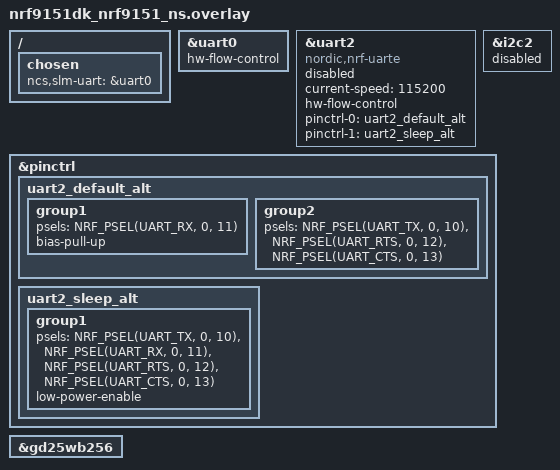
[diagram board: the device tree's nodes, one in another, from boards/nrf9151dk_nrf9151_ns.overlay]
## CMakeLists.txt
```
#
# Copyright (c) 2019 Nordic Semiconductor
#
# SPDX-License-Identifier: LicenseRef-Nordic-5-Clause
#

cmake_minimum_required(VERSION 3.20.0)

find_package(Zephyr REQUIRED HINTS $ENV{ZEPHYR_BASE})
project(serial_lte_modem)

# NORDIC SDK APP START
target_sources(app PRIVATE src/main.c)
target_sources(app PRIVATE src/slm_util.c)
target_sources(app PRIVATE src/slm_ctrl_pin.c)
target_sources(app PRIVATE src/slm_settings.c)
target_sources(app PRIVATE src/slm_at_host.c)
target_sources(app PRIVATE src/slm_at_commands.c)
target_sources(app PRIVATE src/slm_at_socket.c)
target_sources(app PRIVATE src/slm_at_tcp_proxy.c)
target_sources(app PRIVATE src/slm_at_udp_proxy.c)
target_sources(app PRIVATE src/slm_at_icmp.c)
target_sources(app PRIVATE src/slm_at_fota.c)
target_sources(app PRIVATE src/slm_uart_handler.c)
# NORDIC SDK APP END
target_sources_ifdef(CONFIG_SLM_SMS app PRIVATE src/slm_at_sms.c)
target_sources_ifdef(CONFIG_SLM_PPP app PRIVATE src/slm_ppp.c)
target_sources_ifdef(CONFIG_SLM_CMUX app PRIVATE src/slm_cmux.c)

add_subdirectory_ifdef(CONFIG_SLM_GNSS src/gnss)
add_subdirectory_ifdef(CONFIG_SLM_NRF_CLOUD src/nrfcloud)
add_subdirectory_ifdef(CONFIG_SLM_MQTTC src/mqtt_c)
add_subdirectory_ifdef(CONFIG_SLM_HTTPC src/http_c)
add_subdirectory_ifdef(CONFIG_SLM_TWI src/twi)
add_subdirectory_ifdef(CONFIG_SLM_GPIO src/gpio)
add_subdirectory_ifdef(CONFIG_SLM_CARRIER src/lwm2m_carrier)
add_subdirectory_ifdef(CONFIG_SLM_NATIVE_TLS src/nativetls)
if (CONFIG_SLM_FTPC OR CONFIG_SLM_TFTPC)
        add_subdirectory(src/ftp_c)
endif()

zephyr_include_directories(src)
```

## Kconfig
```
#
# Copyright (c) 2019 Nordic Semiconductor
#
# SPDX-License-Identifier: LicenseRef-Nordic-5-Clause
#

source "Kconfig.zephyr"

menu "Nordic Serial LTE Modem"

config SLM_CUSTOMER_VERSION
	string "Customer version string"
	help
	   This version is reported together with baseline versions by AT command "#XSLMVER".

config SLM_AT_MAX_PARAM
	int "Maximum number of parameters in AT command"
	default 42

#
# external XTAL for UART
#
config SLM_EXTERNAL_XTAL
	bool "Use external XTAL for UARTE"
	default y

#
# AT command terminator
#
choice
	prompt "Termination mode"
	default SLM_CR_LF_TERMINATION
	help
		Sets the command terminator used by the serial terminal.
		Available options are:
		-  CR termination
		-  LF termination
		-  CR+LF termination
	config SLM_CR_TERMINATION
		bool "CR termination"
	config SLM_LF_TERMINATION
		bool "LF termination"
	config SLM_CR_LF_TERMINATION
		bool "CR+LF termination"
endchoice

#
# UART buffers (when CMUX is not in use)
#
config SLM_UART_RX_BUF_COUNT
	int "Receive buffers for UART"
	range 2 4
	default 3
	help
	  Amount of buffers for receiving (RX) UART traffic.
	  If the buffers are full, UART RX will be disabled until the buffers are processed.
	  These buffers are not used when CMUX is in use.

config SLM_UART_RX_BUF_SIZE
	int "Receive buffer size for UART"
	range 128 4096
	default 256
	help
	  Amount of received (RX), unprocessed, UART traffic that can be held by single buffer.
	  These buffers are not used when CMUX is in use.

config SLM_UART_TX_BUF_SIZE
	int "Send buffer size for UART"
	range 128 4096
	default 256
	help
	  Amount of UART traffic waiting to be sent (TX), that can be held.
	  If the buffers are full, will send synchronously.
	  These buffers are not used when CMUX is in use.

#
# GPIO functionality
#
config SLM_START_SLEEP
	bool "Enter sleep on startup"
	help
	  If enabled, the SiP is put into deep sleep when powered on.
	  It can then be started using SLM_POWER_PIN.

config SLM_POWER_PIN
	int "Power pin"
	default -1
	help
	  Interface GPIO pin used to put the SiP into deep sleep and wake up from it or exit idle.
	  The pin is configured with a pull up and must be pulled down shortly to perform one power off or wake up operation.

config SLM_INDICATE_PIN
	int "Indicate pin"
	default -1
	help
	  Interface GPIO pin used to indicate that data is available when SLM is idle (after #XSLEEP=2 AT command).

config SLM_INDICATE_TIME
	int "Indication period"
	default 100
	help
	  GPIO active indication time in milliseconds. This setting specify the period length for the pin to be active

#
# LTE network automatic attach
#
config SLM_AUTO_CONNECT
	bool "Automatically connect to the LTE network on start-up or after a reset"
	help
	  Enables automatic connection to the LTE network using the PDN configuration defined in 'slm_auto_connect.h'.

#
# TCP/TLS proxy
#
config SLM_TCP_POLL_TIME
	int "Poll time-out in seconds for TCP connection"
	default 10

config SLM_UDP_POLL_TIME
	int "Poll time-out in seconds for UDP connection"
	default 10

#
# Data mode
#
config SLM_DATAMODE_TERMINATOR
	string "Pattern string to terminate data mode"
	default "+++"
	help
	  Use a pattern to terminate data mode

config SLM_DATAMODE_URC
	bool "Send URC in data mode"
	help
	  Report result of data mode sending

config SLM_DATAMODE_BUF_SIZE
	int "Buffer size for data mode"
	range 1024 8192
	default 4096
	help
	  Size of the buffer for data received in data mode.

#
# Configurable services
#
config SLM_SMS
	bool "SMS support in SLM"
	default y
	select SMS
	help
	  Support SMS send/receive in plain text

config SLM_GNSS
	bool "GNSS support in SLM"
	default y

config SLM_NRF_CLOUD
	bool "nRF Cloud support in SLM"
	default y

config SLM_FULL_FOTA
	bool "Full modem FOTA support in SLM"
	default n
	depends on !BOARD_THINGY91_NRF9160_NS

config SLM_PPP
	bool "PPP support in SLM"
	help
	  When enabled, SLM automatically brings up/down the PPP link
	  when the LTE link (default PDN) is connected/disconnected,
	  regardless of what is done with AT#XPPP.

if SLM_PPP

config SLM_PPP_FALLBACK_MTU
	int "Fallback MTU to be used by PPP"
	default 1280
	help
	  PPP tries to retrieve the cellular link MTU from the modem (using `AT+CGCONTRDP=0`).
	  If no MTU is returned by the modem, this value will be used as a fallback.
	  The MTU will be used for sending and receiving of data on both the PPP and cellular links.

endif

config SLM_CMUX
	bool "CMUX support in SLM"

config SLM_CMUX_UART_BUFFER_SIZE
	int "UART buffer size for CMUX"
	depends on SLM_CMUX
	default 6000
	help
	  Size of the buffer for data received in CMUX mode.
	  Same buffer size is used for both RX and TX.

config SLM_CMUX_NOTIFICATION_TX_BUFFER_SIZE
	int "TX buffer size for unsolicited notifications in CMUX"
	depends on SLM_CMUX
	default 4096
	help
	  Unsolicited notifications need to be buffered with CMUX.
	  Notifications longer than this size will get truncated.
	  This can be reduced if your use cases do not require lengthy notifications.
	  Note: %NCELLMEAS notifications can be nearly 4kB in size,
	  which explains the default value.

if SLM_CMUX && SLM_PPP

config SLM_MODEM_CELLULAR
	bool "Compatibility with cellular modem driver"
	help
	  Enables compatibility with a host that uses the cellular modem driver. Compared to clients,
	  such as pppd, the cellular modem driver retains more control on how the PPP link
	  is brought up and down.

config SLM_CMUX_AUTOMATIC_FALLBACK_ON_PPP_STOPPAGE
	bool "AT channel automatic fallback to DLCI 1 when PPP stops."
	default y if SLM_MODEM_CELLULAR
	help
	  This is mainly intended for compatibility with Zephyr's cellular modem driver.
	  If enabled, when PPP stops (which happens automatically when the LTE link goes down)
	  CMUX will make the AT channel be on DLCI 1. This only has an effect if it had been
	  configured to be elsewhere, e.g. with AT#XCMUX=2.

endif

if SLM_CMUX || SLM_PPP

config SLM_MODEM_PIPE_TIMEOUT
	int "Timeout for the CMUX and PPP modem pipe operations in seconds"
	default 10

endif

config SLM_SKIP_READY_MSG
	bool "Skip ready message"
	help
	  Skip sending the ready message when the application is powered on.


module = SLM
module-str = serial modem
source "${ZEPHYR_BASE}/subsys/logging/Kconfig.template.log_config"

rsource "src/ftp_c/Kconfig"
rsource "src/mqtt_c/Kconfig"
rsource "src/http_c/Kconfig"
rsource "src/twi/Kconfig"
rsource "src/gpio/Kconfig"
rsource "src/lwm2m_carrier/Kconfig"
rsource "src/gnss/Kconfig"
rsource "src/nativetls/Kconfig"

endmenu
```

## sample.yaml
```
sample:
  name: Serial LTE Modem
tests:
  applications.serial_lte_modem:
    sysbuild: true
    build_only: true
    platform_allow:
      - nrf9160dk/nrf9160/ns
      - nrf9161dk/nrf9161/ns
      - nrf9151dk/nrf9151/ns
      - nrf9131ek/nrf9131/ns
      - thingy91/nrf9160/ns
      - thingy91x/nrf9151/ns
    integration_platforms:
      - nrf9160dk/nrf9160/ns
      - nrf9161dk/nrf9161/ns
      - nrf9151dk/nrf9151/ns
      - nrf9131ek/nrf9131/ns
      - thingy91/nrf9160/ns
      - thingy91x/nrf9151/ns
    tags:
      - ci_build
      - sysbuild
      - ci_applications_serial_lte_modem
  applications.serial_lte_modem.extmcu:
    sysbuild: true
    build_only: true
    extra_args:
      - EXTRA_DTC_OVERLAY_FILE="overlay-external-mcu.overlay"
    extra_configs:
      - CONFIG_SLM_POWER_PIN=31
      - CONFIG_SLM_INDICATE_PIN=30
    platform_allow:
      - nrf9160dk/nrf9160/ns
      - nrf9161dk/nrf9161/ns
      - nrf9151dk/nrf9151/ns
    integration_platforms:
      - nrf9151dk/nrf9151/ns
    tags:
      - ci_build
      - sysbuild
      - ci_applications_serial_lte_modem
  applications.serial_lte_modem.ppp_without_cmux:
    sysbuild: true
    build_only: true
    extra_args:
      - EXTRA_CONF_FILE="overlay-ppp.conf"
      - EXTRA_DTC_OVERLAY_FILE="overlay-ppp-without-cmux.overlay"
    platform_allow:
      - nrf9160dk/nrf9160/ns
      - nrf9161dk/nrf9161/ns
      - nrf9151dk/nrf9151/ns
      - nrf9131ek/nrf9131/ns
      - thingy91/nrf9160/ns
      - thingy91x/nrf9151/ns
    integration_platforms:
      - nrf9151dk/nrf9151/ns
    tags:
      - ci_build
      - sysbuild
      - ci_applications_serial_lte_modem
  applications.serial_lte_modem.ppp_without_cmux_power_indicate_pin:
    sysbuild: true
    build_only: true
    extra_args:
      - EXTRA_CONF_FILE="overlay-ppp.conf"
      - EXTRA_DTC_OVERLAY_FILE="overlay-ppp-without-cmux.overlay"
    extra_configs:
      - CONFIG_SLM_POWER_PIN=31
      - CONFIG_SLM_INDICATE_PIN=30
    platform_allow:
      - nrf9160dk/nrf9160/ns
      - nrf9161dk/nrf9161/ns
      - nrf9151dk/nrf9151/ns
      - nrf9131ek/nrf9131/ns
      - thingy91/nrf9160/ns
      - thingy91x/nrf9151/ns
    integration_platforms:
      - nrf9151dk/nrf9151/ns
    tags:
      - ci_build
      - sysbuild
      - ci_applications_serial_lte_modem
  applications.serial_lte_modem.ppp_cmux_linux:
    sysbuild: true
    build_only: true
    extra_args:
      - EXTRA_CONF_FILE="overlay-ppp-cmux-linux.conf"
    platform_allow:
      - nrf9160dk/nrf9160/ns
      - nrf9161dk/nrf9161/ns
      - nrf9151dk/nrf9151/ns
      - nrf9131ek/nrf9131/ns
      - thingy91/nrf9160/ns
      - thingy91x/nrf9151/ns
    integration_platforms:
      - nrf9151dk/nrf9151/ns
    tags:
      - ci_build
      - sysbuild
      - ci_applications_serial_lte_modem
  applications.serial_lte_modem.ppp_cmux_linux_power_indicate_pin:
    sysbuild: true
    build_only: true
    extra_args:
      - EXTRA_CONF_FILE="overlay-ppp-cmux-linux.conf"
    extra_configs:
      - CONFIG_SLM_POWER_PIN=31
      - CONFIG_SLM_INDICATE_PIN=30
    platform_allow:
      - nrf9160dk/nrf9160/ns
      - nrf9161dk/nrf9161/ns
      - nrf9151dk/nrf9151/ns
      - nrf9131ek/nrf9131/ns
      - thingy91/nrf9160/ns
      - thingy91x/nrf9151/ns
    integration_platforms:
      - nrf9151dk/nrf9151/ns
    tags:
      - ci_build
      - sysbuild
      - ci_applications_serial_lte_modem
  applications.serial_lte_modem.ppp_cmux_zephyr_with_extmcu:
    sysbuild: true
    build_only: true
    extra_args:
      - EXTRA_CONF_FILE="overlay-cmux.conf;overlay-ppp.conf;overlay-zephyr-modem.conf"
      - EXTRA_DTC_OVERLAY_FILE="overlay-external-mcu.overlay"
    platform_allow:
      - nrf9160dk/nrf9160/ns
      - nrf9161dk/nrf9161/ns
      - nrf9151dk/nrf9151/ns
      - nrf9131ek/nrf9131/ns
      - thingy91/nrf9160/ns
      - thingy91x/nrf9151/ns
    integration_platforms:
      - nrf9151dk/nrf9151/ns
    tags:
      - ci_build
      - sysbuild
      - ci_applications_serial_lte_modem
  applications.serial_lte_modem.ppp_cmux_zephyr_with_nrf52840_on_nrf9160dk:
    sysbuild: true
    build_only: true
    extra_args:
      - EXTRA_CONF_FILE="overlay-cmux.conf;overlay-ppp.conf;overlay-zephyr-modem.conf;overlay-zephyr-modem-nrf9160dk-nrf52840.conf"
      - EXTRA_DTC_OVERLAY_FILE="overlay-zephyr-modem-nrf9160dk-nrf52840.overlay"
    platform_allow:
      - nrf9160dk/nrf9160/ns
    integration_platforms:
      - nrf9160dk/nrf9160/ns
    tags:
      - ci_build
      - sysbuild
      - ci_applications_serial_lte_modem
  applications.serial_lte_modem.memfault:
    sysbuild: true
    build_only: true
    extra_args:
      - EXTRA_CONF_FILE=overlay-memfault.conf
    extra_configs:
      - CONFIG_MEMFAULT_NCS_PROJECT_KEY="dummy-key"
    platform_allow:
      - nrf9160dk/nrf9160/ns
      - nrf9161dk/nrf9161/ns
      - nrf9151dk/nrf9151/ns
      - nrf9131ek/nrf9131/ns
      - thingy91/nrf9160/ns
      - thingy91x/nrf9151/ns
    integration_platforms:
      - nrf9151dk/nrf9151/ns
    tags:
      - ci_build
      - sysbuild
      - ci_applications_serial_lte_modem
  applications.serial_lte_modem.native_tls:
    sysbuild: true
    build_only: true
    extra_args: EXTRA_CONF_FILE=overlay-native_tls.conf
    platform_allow:
      - nrf9160dk/nrf9160/ns
      - nrf9161dk/nrf9161/ns
      - nrf9151dk/nrf9151/ns
      - nrf9131ek/nrf9131/ns
      - thingy91x/nrf9151/ns
    integration_platforms:
      - nrf9151dk/nrf9151/ns
    tags:
      - ci_build
      - sysbuild
      - ci_applications_serial_lte_modem
  applications.serial_lte_modem.lwm2m_carrier:
    sysbuild: true
    build_only: true
    extra_args: EXTRA_CONF_FILE=overlay-carrier.conf
    platform_allow:
      - nrf9160dk/nrf9160/ns
      - nrf9161dk/nrf9161/ns
      - nrf9151dk/nrf9151/ns
      - nrf9131ek/nrf9131/ns
      - thingy91x/nrf9151/ns
    integration_platforms:
      - nrf9151dk/nrf9151/ns
    tags:
      - ci_build
      - sysbuild
      - ci_applications_serial_lte_modem
  applications.serial_lte_modem.lwm2m_carrier.softbank:
    sysbuild: true
    build_only: true
    extra_args:
      - EXTRA_CONF_FILE="overlay-carrier.conf;overlay-carrier-softbank.conf"
      - SB_EXTRA_CONF_FILE=sysbuild-softbank.conf
    platform_allow:
      - nrf9160dk/nrf9160/ns
      - nrf9151dk/nrf9151/ns
    integration_platforms:
      - nrf9160dk/nrf9160/ns
    tags:
      - ci_build
      - sysbuild
      - ci_applications_serial_lte_modem
  applications.serial_lte_modem.lwm2m_carrier.lgu:
    sysbuild: true
    build_only: true
    extra_args: EXTRA_CONF_FILE="overlay-carrier.conf;overlay-carrier-lgu.conf"
    platform_allow:
      - nrf9151dk/nrf9151/ns
    integration_platforms:
      - nrf9151dk/nrf9151/ns
    tags:
      - ci_build
      - sysbuild
      - ci_applications_serial_lte_modem
  applications.serial_lte_modem.lwm2m_carrier.thingy91:
    sysbuild: true
    build_only: true
    extra_args:
      - EXTRA_CONF_FILE=overlay-carrier.conf
      - SB_CONFIG_THINGY91_STATIC_PARTITIONS_LWM2M_CARRIER=y
    platform_allow:
      - thingy91/nrf9160/ns
    integration_platforms:
      - thingy91/nrf9160/ns
    tags:
      - ci_build
      - sysbuild
      - ci_applications_serial_lte_modem
  applications.serial_lte_modem.tracing:
    sysbuild: true
    build_only: true
    platform_allow:
      - nrf9151dk/nrf9151/ns
      - nrf9160dk/nrf9160/ns
      - nrf9161dk/nrf9161/ns
      - thingy91/nrf9160/ns
      - thingy91x/nrf9151/ns
    integration_platforms:
      - nrf9151dk/nrf9151/ns
      - nrf9160dk/nrf9160/ns
      - nrf9161dk/nrf9161/ns
      - thingy91/nrf9160/ns
      - thingy91x/nrf9151/ns
    tags:
      - ci_build
      - sysbuild
      - ci_applications_serial_lte_modem
    extra_args:
      - serial_lte_modem_SNIPPET=nrf91-modem-trace-uart
```

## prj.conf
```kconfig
#
# Copyright (c) 2020 Nordic Semiconductor ASA
#
# SPDX-License-Identifier: LicenseRef-Nordic-5-Clause
#
# General config
CONFIG_LOG=y
CONFIG_ASSERT=y
CONFIG_ASSERT_VERBOSE=n
CONFIG_LOG_DEFAULT_LEVEL=3
CONFIG_STACK_SENTINEL=y
CONFIG_PICOLIBC_IO_FLOAT=y
CONFIG_RING_BUFFER=y
CONFIG_REBOOT=y
CONFIG_EVENTFD=y

# Segger RTT
CONFIG_USE_SEGGER_RTT=y
# Where console messages (printk) are output.
# By itself, SLM does not output any.
CONFIG_RTT_CONSOLE=y
CONFIG_UART_CONSOLE=n
# Where SLM logs are output.
CONFIG_LOG_BACKEND_RTT=y
CONFIG_LOG_BACKEND_UART=n
# Increase the buffer so that all SLM boot logs fit into the buffer.
# Because J-Link RTT Viewer has to be connected after the bootup,
# only logs that fit into the buffer are shown. This is especially useful in showing
# errors if SLM does not start properly.
CONFIG_SEGGER_RTT_BUFFER_SIZE_UP=2048

# Network
CONFIG_NETWORKING=y
CONFIG_NET_SOCKETS=y
CONFIG_NET_NATIVE=n
CONFIG_NET_IPV4=y
CONFIG_NET_IPV6=y

# Modem library
CONFIG_NRF_MODEM_LIB=y
CONFIG_AT_CMD_CUSTOM=y
# Align the max FD entry to NRF_MODEM_MAX_SOCKET_COUNT(8)
CONFIG_ZVFS_OPEN_MAX=8

# Handle modem fault
CONFIG_NRF_MODEM_LIB_ON_FAULT_APPLICATION_SPECIFIC=y

# Use GPIO
CONFIG_GPIO=y
CONFIG_GPIO_NRFX=y

# UART interface
CONFIG_SERIAL=y
CONFIG_UART_USE_RUNTIME_CONFIGURE=y
CONFIG_UART_ASYNC_API=y
CONFIG_NRFX_TIMER2=y

# Stacks and heaps
CONFIG_MAIN_STACK_SIZE=4096
CONFIG_HEAP_MEM_POOL_SIZE=16384
CONFIG_SYSTEM_WORKQUEUE_STACK_SIZE=4096
CONFIG_AT_MONITOR_HEAP_SIZE=4096

# Device power management
CONFIG_PM_DEVICE=y

# FOTA
CONFIG_HTTP_PARSER_URL=y
CONFIG_FOTA_DOWNLOAD=y
CONFIG_FOTA_DOWNLOAD_PROGRESS_EVT=y
CONFIG_DFU_TARGET=y
CONFIG_DOWNLOADER=y
CONFIG_DOWNLOADER_STACK_SIZE=4096
CONFIG_DOWNLOADER_MAX_FILENAME_SIZE=2048
CONFIG_BOOTLOADER_MCUBOOT=y
CONFIG_IMG_MANAGER=y

# FLASH
CONFIG_FLASH=y
CONFIG_FLASH_PAGE_LAYOUT=y
CONFIG_FLASH_MAP=y
CONFIG_STREAM_FLASH=y
CONFIG_MPU_ALLOW_FLASH_WRITE=y
CONFIG_IMG_ERASE_PROGRESSIVELY=y

# Settings
CONFIG_SETTINGS=y
CONFIG_SETTINGS_NVS=y
CONFIG_NVS=y

# nRF Cloud
CONFIG_NRF_CLOUD=y
CONFIG_NRF_CLOUD_MQTT=y
CONFIG_NRF_CLOUD_FOTA=n
CONFIG_NRF_CLOUD_AGNSS=y
CONFIG_NRF_CLOUD_AGNSS_FILTERED=n
CONFIG_NRF_CLOUD_PGPS=n
CONFIG_NRF_CLOUD_LOCATION=y
CONFIG_NRF_CLOUD_LOG_LEVEL_INF=y
CONFIG_NRF_CLOUD_GPS_LOG_LEVEL_INF=y
CONFIG_NRF_CLOUD_CLIENT_ID_SRC_INTERNAL_UUID=y
CONFIG_NRF_CLOUD_WIFI_LOCATION_ENCODE_OPT_MAC_RSSI=y
CONFIG_DATE_TIME=y
CONFIG_MODEM_INFO=y
CONFIG_MODEM_INFO_ADD_DATE_TIME=n

# UUID and JWT
CONFIG_MODEM_JWT=y

# MQTT client
#CONFIG_MQTT_KEEPALIVE=60
CONFIG_MQTT_CLEAN_SESSION=y

# AT command helper libraries
CONFIG_AT_PARSER=y
CONFIG_AT_MONITOR=y

# Eventfd's to use with AT-commands.
CONFIG_ZVFS_EVENTFD_MAX=2

# Disable TF-M logging.
# TF-M log sending will block until remote end is ready, when HWFC is used on UART1.
CONFIG_TFM_LOG_LEVEL_SILENCE=y

#
# SLM-specific configurations
#
CONFIG_SLM_CUSTOMER_VERSION=""
CONFIG_SLM_EXTERNAL_XTAL=n

# debug options
#CONFIG_LOG_BUFFER_SIZE=16384
#CONFIG_SLM_LOG_LEVEL_DBG=y
#CONFIG_LOG_PRINTK=n
#CONFIG_LOG_MODE_IMMEDIATE=y

# For using external GNSS antenna
#CONFIG_MODEM_ANTENNA=y
#CONFIG_MODEM_ANTENNA_GNSS_EXTERNAL=y
```

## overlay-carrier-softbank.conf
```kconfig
#
# Copyright (c) 2024 Nordic Semiconductor
#
# SPDX-License-Identifier: LicenseRef-Nordic-5-Clause
#

# SoftBank
CONFIG_LWM2M_CARRIER_SOFTBANK=y
CONFIG_LWM2M_CARRIER_SOFTBANK_DIVIDED_FOTA=y

# Application FOTA
CONFIG_DFU_TARGET_MCUBOOT=y
CONFIG_IMG_MANAGER=y
CONFIG_STREAM_FLASH=y
CONFIG_STREAM_FLASH_ERASE=y
CONFIG_FLASH_MAP=y
```

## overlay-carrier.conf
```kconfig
#
# Copyright (c) 2022 Nordic Semiconductor ASA
#
# SPDX-License-Identifier: LicenseRef-Nordic-5-Clause
#

CONFIG_LWM2M_CARRIER=y

# LwM2M carrier is only compiled for hard-float
CONFIG_FP_HARDABI=y

# PDN management support
CONFIG_PDN=y

# Download client for DFU
CONFIG_DOWNLOADER_MAX_FILENAME_SIZE=230

# Modem info
CONFIG_MODEM_INFO_BUFFER_SIZE=512

# Enable LwM2M carrier support in SLM
CONFIG_SLM_CARRIER=y
CONFIG_SLM_AUTO_CONNECT=y
CONFIG_SLM_CUSTOMER_VERSION="lwm2m_carrier"

# Enable LwM2M carrier settings support
CONFIG_LWM2M_CARRIER_SETTINGS=y

# DFU target library
CONFIG_DFU_TARGET=y

# IPv4 (IPv6 is enabled by default)
CONFIG_NET_IPV4=y
```

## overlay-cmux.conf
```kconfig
#
# Copyright (c) 2023 Nordic Semiconductor ASA
#
# SPDX-License-Identifier: LicenseRef-Nordic-5-Clause
#

CONFIG_SLM_CMUX=y
CONFIG_SLM_SKIP_READY_MSG=y

# Zephyr modem subsystem
CONFIG_MODEM_MODULES=y
CONFIG_MODEM_CMUX=y
CONFIG_MODEM_BACKEND_UART=y
CONFIG_MODEM_BACKEND_UART_ASYNC_TRANSMIT_TIMEOUT_MS=1000

# debug options
#CONFIG_MODEM_CMUX_LOG_LEVEL_DBG=y
#CONFIG_MODEM_MODULES_LOG_LEVEL_DBG=y
```

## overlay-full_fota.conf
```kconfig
#
# Copyright (c) 2023 Nordic Semiconductor ASA
#
# SPDX-License-Identifier: LicenseRef-Nordic-5-Clause
#

# This overlay requires a board with an external flash.
# For nRF9160 DKs, only revisions 0.14.0 and later have one.

# Enable external flash for full FOTA
CONFIG_SPI_NOR=y

# Full modem FOTA required settings
CONFIG_DFU_TARGET_STREAM=y
CONFIG_DFU_TARGET_FULL_MODEM=y
CONFIG_FMFU_FDEV_SKIP_PREVALIDATION=n
CONFIG_MBEDTLS_LEGACY_CRYPTO_C=y
CONFIG_MBEDTLS_SHA256_C=y
CONFIG_FMFU_FDEV=y
CONFIG_ZCBOR=y
CONFIG_STREAM_FLASH_INSPECT=n

# Enable full FOTA support
CONFIG_SLM_FULL_FOTA=y
```

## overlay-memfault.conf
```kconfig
#
# Copyright (c) 2025 Nordic Semiconductor
#
# SPDX-License-Identifier: LicenseRef-Nordic-5-Clause
#

CONFIG_MEMFAULT=y
CONFIG_MEMFAULT_HTTP_PERIODIC_UPLOAD=y
CONFIG_MODEM_KEY_MGMT=y
CONFIG_MEMFAULT_LOGGING_ENABLE=y
CONFIG_MEMFAULT_HTTP_ENABLE=y
CONFIG_MEMFAULT_NCS_LTE_METRICS=y
CONFIG_MEMFAULT_NCS_STACK_METRICS=y
CONFIG_MEMFAULT_NCS_INTERNAL_FLASH_BACKED_COREDUMP=y
CONFIG_MEMFAULT_NCS_DEVICE_ID_IMEI=y
CONFIG_MEMFAULT_LOGGING_RAM_SIZE=4096
CONFIG_MEMFAULT_HEAP_STATS=y
CONFIG_MEMFAULT_HTTP_DEDICATED_WORKQUEUE_STACK_SIZE=1560
CONFIG_MEMFAULT_COREDUMP_FULL_THREAD_STACKS=y
CONFIG_MEMFAULT_EVENT_STORAGE_SIZE=2048
CONFIG_MEMFAULT_NCS_POST_COREDUMP_ON_NETWORK_CONNECTED=y
CONFIG_PDN=y
CONFIG_LTE_LINK_CONTROL=y
CONFIG_LTE_LC_EDRX_MODULE=y
CONFIG_LTE_LC_PSM_MODULE=y

# Memfault depends on POSIX, disable unneeded POSIX features
CONFIG_POSIX_FILE_SYSTEM=n
```

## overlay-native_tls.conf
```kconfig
#
# Copyright (c) 2023 Nordic Semiconductor ASA
#
# SPDX-License-Identifier: LicenseRef-Nordic-5-Clause
#

CONFIG_SLM_NATIVE_TLS=y
# Enable offloading with TLS_NATIVE.
CONFIG_NET_SOCKETS_OFFLOAD_DISPATCHER=y
# Enable legacy crypto support
CONFIG_NRF_SECURITY=y
CONFIG_NORDIC_SECURITY_BACKEND=y
CONFIG_MBEDTLS_PSA_CRYPTO_C=y
# Enable TLS client and server via Mbed TLS library
CONFIG_MBEDTLS=y
CONFIG_MBEDTLS_TLS_LIBRARY=y
CONFIG_MBEDTLS_SSL_SRV_C=y
CONFIG_MBEDTLS_CIPHER=y
# Reserve enough settings space for the certificates
CONFIG_PM_PARTITION_SIZE_SETTINGS_STORAGE=0x4000
# Set maximum TLS contexts.
# Increase also CONFIG_ZVFS_OPEN_MAX, if you need more TLS contexts.
CONFIG_NET_SOCKETS_TLS_MAX_CONTEXTS=2
CONFIG_ZVFS_OPEN_MAX=10
# Set packet sizes for incoming and outcoming packets.
# If handshake packet (likely CA chain) or TLS record size exceeds these
# values, increase the corresponding value and the CONFIG_MBEDTLS_HEAP_SIZE.
CONFIG_MBEDTLS_SSL_IN_CONTENT_LEN=8192
CONFIG_MBEDTLS_SSL_OUT_CONTENT_LEN=4096
CONFIG_MBEDTLS_ENABLE_HEAP=y
CONFIG_MBEDTLS_HEAP_SIZE=65536
# Enable TLS protocol options
CONFIG_NET_SOCKETS_SOCKOPT_TLS=y
CONFIG_NET_SOCKETS_TLS_SET_MAX_FRAGMENT_LENGTH=y
CONFIG_MBEDTLS_SSL_SERVER_NAME_INDICATION=y
# Enable DTLS
CONFIG_MBEDTLS_DTLS=y
CONFIG_MBEDTLS_SSL_DTLS_CONNECTION_ID=y
CONFIG_NET_SOCKETS_ENABLE_DTLS=y
CONFIG_NET_IPV4=y
# Maximum timeout for TCP, TLS and DTLS connections
CONFIG_NET_SOCKETS_CONNECT_TIMEOUT=30000
# Enable AES
CONFIG_MBEDTLS_AES_C=y
CONFIG_MBEDTLS_CCM_C=y
CONFIG_MBEDTLS_GCM_C=y
CONFIG_MBEDTLS_CIPHER_MODE_CBC=y
CONFIG_MBEDTLS_CIPHER_PADDING_PKCS7=y
# Enable ECC
CONFIG_MBEDTLS_ECP_C=y
CONFIG_PSA_WANT_ECC_SECP_R1_256=y
CONFIG_PSA_WANT_ECC_SECP_R1_384=y
# Enable ECDSA
CONFIG_MBEDTLS_ECDSA_C=y
CONFIG_PSA_WANT_ALG_ECDSA=y
CONFIG_MBEDTLS_ECDSA_DETERMINISTIC=y
CONFIG_PSA_WANT_ALG_DETERMINISTIC_ECDSA=y
CONFIG_PSA_WANT_KEY_TYPE_ECC_KEY_PAIR_IMPORT=y # dep for DETERMINISTIC_ECDSA
CONFIG_PSA_WANT_ALG_HMAC=y # dep for DETERMINISTIC_ECDSA
# Enable ECDH
CONFIG_MBEDTLS_KEY_EXCHANGE_ECDH_RSA_ENABLED=y
CONFIG_MBEDTLS_ECDH_C=y
CONFIG_PSA_WANT_ALG_ECDH=y
# Enable EDCHE
CONFIG_MBEDTLS_KEY_EXCHANGE_ECDHE_ECDSA_ENABLED=y
CONFIG_MBEDTLS_KEY_EXCHANGE_ECDHE_RSA_ENABLED=y
# Enable RSA
CONFIG_MBEDTLS_RSA_C=y
CONFIG_MBEDTLS_KEY_EXCHANGE_RSA_ENABLED=y
CONFIG_MBEDTLS_PKCS1_V15=y
CONFIG_MBEDTLS_MPI_MAX_SIZE=512
CONFIG_PSA_WANT_KEY_TYPE_RSA_PUBLIC_KEY=y
CONFIG_PSA_WANT_RSA_KEY_SIZE_2048=y
CONFIG_PSA_WANT_RSA_KEY_SIZE_4096=y
# Enable SHA
CONFIG_MBEDTLS_SHA256_C=y
CONFIG_MBEDTLS_SHA512_C=y
# Enable PSK key exchange
CONFIG_MBEDTLS_KEY_EXCHANGE_PSK_ENABLED=y

# Disable MBEDTLS modules
CONFIG_MBEDTLS_CTR_DRBG_C=n
CONFIG_MBEDTLS_CHACHA20_C=n
CONFIG_MBEDTLS_POLY1305_C=n
CONFIG_MBEDTLS_DHM_C=n
CONFIG_MBEDTLS_CMAC_C=n
# Disable key exchange algorithms
CONFIG_MBEDTLS_KEY_EXCHANGE_DHE_PSK_ENABLED=n
CONFIG_MBEDTLS_KEY_EXCHANGE_DHE_RSA_ENABLED=n
# Disable hash functions
CONFIG_MBEDTLS_SHA1_C=n

# Enable Socket Logging for debug
#CONFIG_NET_LOG=y
#CONFIG_NET_SOCKETS_LOG_LEVEL_DBG=y

# Enable Mbed TLS logs
#CONFIG_MBEDTLS_DEBUG=y
#CONFIG_MBEDTLS_DEBUG_C=y
#CONFIG_MBEDTLS_DEBUG_LEVEL=3
```

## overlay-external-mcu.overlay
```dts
/*
 * Copyright (c) 2024 Nordic Semiconductor ASA
 *
 * SPDX-License-Identifier: LicenseRef-Nordic-5-Clause
 */

/ {
	chosen {
		ncs,slm-uart = &uart2;
	};
};

&uart2 {
	status = "okay";
};

/* uart0 is not needed if no logging is received there. */
&uart0 {
	status = "disabled";
};
```

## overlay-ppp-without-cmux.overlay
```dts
/*
 * Copyright (c) 2023 Nordic Semiconductor ASA
 *
 * SPDX-License-Identifier: LicenseRef-Nordic-5-Clause
 */

/* Include this devicetree overlay only if using PPP without CMUX. */

 / {
	chosen {
		ncs,slm-ppp-uart = &uart1;
	};
};

/* PPP UART. Baud rates other than 115200/230400/1000000 didn't work on uart1. */
&uart1 {
	status = "okay";
	hw-flow-control;
	current-speed = <1000000>;
};
```

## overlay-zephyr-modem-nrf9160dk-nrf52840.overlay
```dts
/*
 * Copyright (c) 2024 Nordic Semiconductor ASA
 *
 * SPDX-License-Identifier: LicenseRef-Nordic-5-Clause
 */

#include <nrf9160/nrf9160dk_uart1_on_if0_3.dtsi>

/ {
	chosen {
		ncs,slm-uart = &uart1;
	};
};

&uart1 {
        current-speed = <115200>;
        hw-flow-control;
};
```

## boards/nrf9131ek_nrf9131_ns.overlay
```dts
/*
 * Copyright (c) 2024 Nordic Semiconductor ASA
 *
 * SPDX-License-Identifier: LicenseRef-Nordic-5-Clause
 */

/ {
	chosen {
		ncs,slm-uart = &uart0;
	};
};

&uart0 {
	status = "okay";
	hw-flow-control;
};
```

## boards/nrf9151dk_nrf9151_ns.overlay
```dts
/*
 * Copyright (c) 2024 Nordic Semiconductor ASA
 *
 * SPDX-License-Identifier: LicenseRef-Nordic-5-Clause
 */

 / {
	chosen {
		ncs,slm-uart = &uart0;
	};
};

&uart0 {
	status = "okay";
	hw-flow-control;
};

&uart2 {
	compatible = "nordic,nrf-uarte";
	current-speed = <115200>;
	status = "disabled";
	hw-flow-control;

	pinctrl-0 = <&uart2_default_alt>;
	pinctrl-1 = <&uart2_sleep_alt>;
	pinctrl-names = "default", "sleep";
};

&i2c2 {
	status = "disabled";
};

&pinctrl {
	uart2_default_alt: uart2_default_alt {
		group1 {
			psels = <NRF_PSEL(UART_RX, 0, 11)>;
			bias-pull-up;
		};
		group2 {
			psels = <NRF_PSEL(UART_TX, 0, 10)>,
				<NRF_PSEL(UART_RTS, 0, 12)>,
				<NRF_PSEL(UART_CTS, 0, 13)>;
		};
	};

	uart2_sleep_alt: uart2_sleep_alt {
		group1 {
			psels = <NRF_PSEL(UART_TX, 0, 10)>,
				<NRF_PSEL(UART_RX, 0, 11)>,
				<NRF_PSEL(UART_RTS, 0, 12)>,
				<NRF_PSEL(UART_CTS, 0, 13)>;
			low-power-enable;
		};
	};
};

/* Enable external flash */
&gd25wb256 {
	status = "okay";
};
```

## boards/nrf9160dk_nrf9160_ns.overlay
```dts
/*
 * Copyright (c) 2021 Nordic Semiconductor ASA
 *
 * SPDX-License-Identifier: LicenseRef-Nordic-5-Clause
 */

/ {
	chosen {
		ncs,slm-uart = &uart0;
	};
};

&uart0 {
	status = "okay";
	hw-flow-control;
};

&uart2 {
	compatible = "nordic,nrf-uarte";
	current-speed = <115200>;
	status = "disabled";
	hw-flow-control;

	pinctrl-0 = <&uart2_default_alt>;
	pinctrl-1 = <&uart2_sleep_alt>;
	pinctrl-names = "default", "sleep";
};

&i2c2 {
	status = "disabled";
};

&pinctrl {
	uart2_default_alt: uart2_default_alt {
		group1 {
			psels = <NRF_PSEL(UART_RX, 0, 11)>;
			bias-pull-up;
		};
		group2 {
			psels = <NRF_PSEL(UART_TX, 0, 10)>,
				<NRF_PSEL(UART_RTS, 0, 12)>,
				<NRF_PSEL(UART_CTS, 0, 13)>;
		};
	};

	uart2_sleep_alt: uart2_sleep_alt {
		group1 {
			psels = <NRF_PSEL(UART_TX, 0, 10)>,
				<NRF_PSEL(UART_RX, 0, 11)>,
				<NRF_PSEL(UART_RTS, 0, 12)>,
				<NRF_PSEL(UART_CTS, 0, 13)>;
			low-power-enable;
		};
	};
};
```

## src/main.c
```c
/*
 * Copyright (c) 2019 Nordic Semiconductor ASA
 *
 * SPDX-License-Identifier: LicenseRef-Nordic-5-Clause
 */
#include <zephyr/logging/log.h>
#include <zephyr/kernel.h>
#include <nrf_modem.h>
#include <hal/nrf_power.h>
#include <modem/nrf_modem_lib.h>
#include <zephyr/dfu/mcuboot.h>
#include <dfu/dfu_target.h>
#include <zephyr/sys/reboot.h>
#include <net/fota_download.h>
#include "slm_at_host.h"
#include "slm_at_fota.h"
#include "slm_settings.h"
#include "slm_util.h"
#include "slm_ctrl_pin.h"

LOG_MODULE_REGISTER(slm, CONFIG_SLM_LOG_LEVEL);

#define SLM_WQ_STACK_SIZE	KB(4)
#define SLM_WQ_PRIORITY		K_LOWEST_APPLICATION_THREAD_PRIO
static K_THREAD_STACK_DEFINE(slm_wq_stack_area, SLM_WQ_STACK_SIZE);

struct k_work_q slm_work_q;

NRF_MODEM_LIB_ON_INIT(lwm2m_init_hook, on_modem_lib_init, NULL);
NRF_MODEM_LIB_ON_DFU_RES(main_dfu_hook, on_modem_dfu_res, NULL);

static void on_modem_lib_init(int ret, void *ctx)
{
	ARG_UNUSED(ctx);

	/** ret: Zero on success, a positive value @em nrf_modem_dfu when executing
	 *  Modem firmware updates, and negative errno on other failures.
	 */
	LOG_INF("lib_modem init: %d", ret);
}

#if defined(CONFIG_NRF_MODEM_LIB_ON_FAULT_APPLICATION_SPECIFIC)
static struct nrf_modem_fault_info modem_fault_info;

static void on_modem_failure(struct k_work *)
{
	int ret;

	rsp_send("\r\n#XMODEM: FAULT,0x%x,0x%x\r\n", modem_fault_info.reason,
		 modem_fault_info.program_counter);

	ret = nrf_modem_lib_shutdown();
	rsp_send("\r\n#XMODEM: SHUTDOWN,%d\r\n", ret);

	ret = nrf_modem_lib_init();
	rsp_send("\r\n#XMODEM: INIT,%d\r\n", ret);
}
K_WORK_DEFINE(modem_failure_work, on_modem_failure);

void nrf_modem_fault_handler(struct nrf_modem_fault_info *fault_info)
{
	modem_fault_info = *fault_info;

	k_work_submit(&modem_failure_work);
}
#endif /* CONFIG_NRF_MODEM_LIB_ON_FAULT_APPLICATION_SPECIFIC */

static void on_modem_dfu_res(int dfu_res, void *ctx)
{
	slm_fota_type = DFU_TARGET_IMAGE_TYPE_MODEM_DELTA;
	slm_fota_stage = FOTA_STAGE_COMPLETE;
	slm_fota_status = FOTA_STATUS_ERROR;
	slm_fota_info = dfu_res;

	switch (dfu_res) {
	case NRF_MODEM_DFU_RESULT_OK:
		LOG_INF("Modem update OK. Running new firmware.");
		slm_fota_status = FOTA_STATUS_OK;
		slm_fota_info = 0;
		break;
	case NRF_MODEM_DFU_RESULT_UUID_ERROR:
	case NRF_MODEM_DFU_RESULT_AUTH_ERROR:
		LOG_ERR("Modem update failed (0x%x). Running old firmware.", dfu_res);
		break;
	case NRF_MODEM_DFU_RESULT_HARDWARE_ERROR:
	case NRF_MODEM_DFU_RESULT_INTERNAL_ERROR:
		LOG_ERR("Fatal error (0x%x) encountered during modem update.", dfu_res);
		break;
	case NRF_MODEM_DFU_RESULT_VOLTAGE_LOW:
		LOG_ERR("Modem update postponed due to low voltage. "
			"Reset the modem once you have sufficient power.");
		slm_fota_stage = FOTA_STAGE_ACTIVATE;
		break;
	default:
		LOG_ERR("Unhandled nrf_modem DFU result code 0x%x.", dfu_res);
		break;
	}
}

static void check_app_fota_status(void)
{
	/** When a TEST image is swapped to primary partition and booted by MCUBOOT,
	 * the API mcuboot_swap_type() will return BOOT_SWAP_TYPE_REVERT. By this type
	 * MCUBOOT means that the TEST image is booted OK and, if it's not confirmed
	 * next, it'll be swapped back to secondary partition and original application
	 * image will be restored to the primary partition (so-called Revert).
	 */
	const int type = mcuboot_swap_type();

	switch (type) {
	/** Attempt to boot the contents of slot 0. */
	case BOOT_SWAP_TYPE_NONE:
		/* Normal reset, nothing happened, do nothing. */
		return;
	/** Swap to slot 1. Absent a confirm command, revert back on next boot. */
	case BOOT_SWAP_TYPE_TEST:
	/** Swap to slot 1, and permanently switch to booting its contents. */
	case BOOT_SWAP_TYPE_PERM:
	/** Swap failed because image to be run is not valid. */
	case BOOT_SWAP_TYPE_FAIL:
		slm_fota_status = FOTA_STATUS_ERROR;
		slm_fota_info = type;
		break;
	/** Swap back to alternate slot. A confirm changes this state to NONE. */
	case BOOT_SWAP_TYPE_REVERT:
		/* Happens on a successful application FOTA. */
		const int ret = boot_write_img_confirmed();

		slm_fota_info = ret;
		slm_fota_status = ret ? FOTA_STATUS_ERROR : FOTA_STATUS_OK;
		break;
	}
	slm_fota_type = DFU_TARGET_IMAGE_TYPE_MCUBOOT;
	slm_fota_stage = FOTA_STAGE_COMPLETE;
}

int lte_auto_connect(void)
{
	int err = 0;
#if defined(CONFIG_SLM_AUTO_CONNECT)
	int ret;
	int n;
	int stat;
	struct network_config {
		/* Refer to AT command manual of %XSYSTEMMODE for system mode settings */
		int lte_m_support;     /* 0 ~ 1 */
		int nb_iot_support;    /* 0 ~ 1 */
		int gnss_support;      /* 0 ~ 1 */
		int lte_preference;    /* 0 ~ 4 */
		/* Refer to AT command manual of +CGDCONT and +CGAUTH for PDN configuration */
		bool pdp_config;       /* PDP context definition required or not */
		char *pdn_fam;         /* PDP type: "IP", "IPV6", "IPV4V6", "Non-IP" */
		char *pdn_apn;         /* Access point name */
		int pdn_auth;          /* PDN authentication protocol 0(None), 1(PAP), 2(CHAP) */
		char *pdn_username;    /* PDN connection authentication username */
		char *pdn_password;    /* PDN connection authentication password */
	};
	const struct network_config cfg = {
#include "slm_auto_connect.h"
	};

	ret = slm_util_at_scanf("AT+CEREG?", "+CEREG: %d,%d", &n, &stat);
	if (ret != 2 || (stat == 1 || stat == 5)) {
		return 0;
	}

	LOG_INF("lte auto connect");
	err = slm_util_at_printf("AT%%XSYSTEMMODE=%d,%d,%d,%d", cfg.lte_m_support,
				  cfg.nb_iot_support, cfg.gnss_support, cfg.lte_preference);
	if (err) {
		LOG_ERR("Failed to configure system mode: %d", err);
		return err;
	}
	if (cfg.pdp_config) {
		err = slm_util_at_printf("AT+CGDCONT=0,%s,%s", cfg.pdn_fam, cfg.pdn_apn);
		if (err) {
			LOG_ERR("Failed to configure PDN: %d", err);
			return err;
		}
	}
	if (cfg.pdp_config && cfg.pdn_auth != 0) {
		err = slm_util_at_printf("AT+CGAUTH=0,%d,%s,%s", cfg.pdn_auth,
					  cfg.pdn_username, cfg.pdn_password);
		if (err) {
			LOG_ERR("Failed to configure AUTH: %d", err);
			return err;
		}
	}
	err = slm_util_at_printf("AT+CFUN=1");
	if (err) {
		LOG_ERR("Failed to turn on radio: %d", err);
		return err;
	}
#endif /* CONFIG_SLM_AUTO_CONNECT */

	return err;
}

int start_execute(void)
{
	int err;

	LOG_INF("Serial LTE Modem");

	slm_ctrl_pin_init();

	/* This will send "READY" or "INIT ERROR" to UART so after this nothing
	 * should be done that can fail
	 */
	err = slm_at_host_init();
	if (err) {
		LOG_ERR("Failed to init at_host: %d", err);
		return err;
	}

	k_work_queue_start(&slm_work_q, slm_wq_stack_area,
			   K_THREAD_STACK_SIZEOF(slm_wq_stack_area),
			   SLM_WQ_PRIORITY, NULL);
	(void)lte_auto_connect();

	return 0;
}

int main(void)
{
	const uint32_t rr = nrf_power_resetreas_get(NRF_POWER_NS);

	nrf_power_resetreas_clear(NRF_POWER_NS, 0x70017);
	LOG_DBG("RR: 0x%08x", rr);

	slm_ctrl_pin_init_gpios();

	/* Init and load settings */
	if (slm_settings_init() != 0) {
		LOG_WRN("Failed to init slm settings");
	}

#if defined(CONFIG_SLM_FULL_FOTA)
	if (slm_modem_full_fota) {
		slm_finish_modem_full_fota();
		slm_fota_type = DFU_TARGET_IMAGE_TYPE_FULL_MODEM;
	}
#endif

	int ret = nrf_modem_lib_init();

	if (ret) {
		LOG_ERR("Modem library init failed, err: %d", ret);
		if (ret != -EAGAIN && ret != -EIO) {
			goto exit;
		} else if (ret == -EIO) {
			LOG_ERR("Please program full modem firmware with the bootloader or "
				"external tools");
		}
	}

	check_app_fota_status();

#if defined(CONFIG_SLM_START_SLEEP)

	if (!(rr & NRF_POWER_RESETREAS_OFF_MASK)) { /* DETECT signal from GPIO */

		slm_ctrl_pin_enter_sleep_no_uninit();
	}
#endif /* CONFIG_SLM_START_SLEEP */

	ret = start_execute();
exit:
	if (ret) {
		LOG_ERR("Failed to start SLM (%d). It's not operational!!!", ret);
	}
	return ret;
}
```

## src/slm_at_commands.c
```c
/*
 * Copyright (c) 2021 Nordic Semiconductor ASA
 *
 * SPDX-License-Identifier: LicenseRef-Nordic-5-Clause
 */
#include <ctype.h>
#include <stdio.h>
#include <string.h>
#include <strings.h>
#include <zephyr/init.h>
#include <zephyr/drivers/uart.h>
#include <zephyr/kernel.h>
#include <zephyr/logging/log_ctrl.h>
#include <zephyr/sys/reboot.h>
#include <zephyr/sys/util.h>
#include <zephyr/types.h>
#include <dfu/dfu_target.h>
#include <modem/at_parser.h>
#include <modem/lte_lc.h>
#include <modem/modem_jwt.h>
#include <modem/nrf_modem_lib.h>
#include "nrf_modem.h"
#include "ncs_version.h"

#include "slm_util.h"
#include "slm_ctrl_pin.h"
#include "slm_settings.h"
#include "slm_at_host.h"
#include "slm_at_tcp_proxy.h"
#include "slm_at_udp_proxy.h"
#include "slm_at_socket.h"
#include "slm_at_icmp.h"
#include "slm_at_sms.h"
#include "slm_at_fota.h"
#if defined(CONFIG_SLM_NATIVE_TLS)
#include "slm_at_cmng.h"
#endif
#if defined(CONFIG_SLM_NRF_CLOUD)
#include "slm_at_nrfcloud.h"
#endif
#if defined(CONFIG_SLM_GNSS)
#include "slm_at_gnss.h"
#endif
#if defined(CONFIG_SLM_FTPC)
#include "slm_at_ftp.h"
#endif
#if defined(CONFIG_SLM_MQTTC)
#include "slm_at_mqtt.h"
#endif
#if defined(CONFIG_SLM_HTTPC)
#include "slm_at_httpc.h"
#endif
#if defined(CONFIG_SLM_TWI)
#include "slm_at_twi.h"
#endif
#if defined(CONFIG_SLM_GPIO)
#include "slm_at_gpio.h"
#endif
#if defined(CONFIG_SLM_CARRIER)
#include "slm_at_carrier.h"
#endif
#if defined(CONFIG_LWM2M_CARRIER_SETTINGS)
#include "slm_at_carrier_cfg.h"
#endif
#if defined(CONFIG_SLM_PPP)
#include "slm_ppp.h"
#endif
#if defined(CONFIG_SLM_CMUX)
#include "slm_cmux.h"
#endif

LOG_MODULE_REGISTER(slm_at, CONFIG_SLM_LOG_LEVEL);

/** @brief Shutdown modes. */
enum sleep_modes {
	SLEEP_MODE_INVALID,
	SLEEP_MODE_DEEP,
	SLEEP_MODE_IDLE
};

#if POWER_PIN_IS_ENABLED
static struct {
	struct k_work_delayable work;
	uint32_t mode;
} sleep_control;
#endif

bool verify_datamode_control(uint16_t time_limit, uint16_t *time_limit_min);

bool slm_is_modem_functional_mode(enum lte_lc_func_mode mode)
{
	int cfun;
	int rc = slm_util_at_scanf("AT+CFUN?", "+CFUN: %d", &cfun);

	return (rc == 1 && cfun == mode);
}

int slm_power_off_modem(void)
{
	/* "[...] there may be a delay until modem is disconnected from the network."
	 * https://infocenter.nordicsemi.com/topic/ps_nrf9160/chapters/pmu/doc/operationmodes/system_off_mode.html
	 * This will return once the modem responds, which means it has actually stopped.
	 * This has been observed to take between 1 and 2 seconds when it is not already stopped.
	 */
	return slm_util_at_printf("AT+CFUN=0");
}

SLM_AT_CMD_CUSTOM(xslmver, "AT#XSLMVER", handle_at_slmver);
static int handle_at_slmver(enum at_parser_cmd_type cmd_type, struct at_parser *, uint32_t)
{
	int ret = -EINVAL;

	if (cmd_type == AT_PARSER_CMD_TYPE_SET) {
		char *libmodem = nrf_modem_build_version();

		if (strlen(CONFIG_SLM_CUSTOMER_VERSION) > 0) {
			rsp_send("\r\n#XSLMVER: %s,\"%s\",\"%s\"\r\n",
				 STRINGIFY(NCS_VERSION_STRING), libmodem,
				 CONFIG_SLM_CUSTOMER_VERSION);
		} else {
			rsp_send("\r\n#XSLMVER: %s,\"%s\"\r\n",
				 STRINGIFY(NCS_VERSION_STRING), libmodem);
		}
		ret = 0;
	}

	return ret;
}

#if POWER_PIN_IS_ENABLED

static void go_sleep_wk(struct k_work *)
{
	if (sleep_control.mode == SLEEP_MODE_IDLE) {
		if (slm_at_host_power_off() == 0) {
			slm_ctrl_pin_enter_idle();
		} else {
			LOG_ERR("failed to power off UART");
		}
	} else if (sleep_control.mode == SLEEP_MODE_DEEP) {
		slm_ctrl_pin_enter_sleep();
	}
}

SLM_AT_CMD_CUSTOM(xsleep, "AT#XSLEEP", handle_at_sleep);
static int handle_at_sleep(enum at_parser_cmd_type cmd_type, struct at_parser *parser,
			   uint32_t)
{
	int ret = -EINVAL;

	if (cmd_type == AT_PARSER_CMD_TYPE_SET) {
		ret = at_parser_num_get(parser, 1, &sleep_control.mode);
		if (ret) {
			return -EINVAL;
		}
		if (sleep_control.mode == SLEEP_MODE_DEEP ||
		    sleep_control.mode == SLEEP_MODE_IDLE) {
			k_work_reschedule(&sleep_control.work, SLM_UART_RESPONSE_DELAY);
		} else {
			ret = -EINVAL;
		}
	} else if (cmd_type == AT_PARSER_CMD_TYPE_TEST) {
		rsp_send("\r\n#XSLEEP: (%d,%d)\r\n", SLEEP_MODE_DEEP, SLEEP_MODE_IDLE);
		ret = 0;
	}

	return ret;
}

#endif /* POWER_PIN_IS_ENABLED */

static void final_call(void (*func)(void))
{
	/* Delegate the final call to a worker so that the "OK" response is properly sent. */
	static struct k_work_delayable worker;

	k_work_init_delayable(&worker, (k_work_handler_t)func);
	k_work_schedule(&worker, SLM_UART_RESPONSE_DELAY);
}

static void slm_shutdown(void)
{
	slm_at_host_uninit();
	slm_power_off_modem();
	LOG_PANIC();
	slm_ctrl_pin_enter_shutdown();
}

SLM_AT_CMD_CUSTOM(xshutdown, "AT#XSHUTDOWN", handle_at_shutdown);
static int handle_at_shutdown(enum at_parser_cmd_type cmd_type, struct at_parser *, uint32_t)
{
	if (cmd_type != AT_PARSER_CMD_TYPE_SET) {
		return -EINVAL;
	}

	final_call(slm_shutdown);
	return 0;
}

FUNC_NORETURN void slm_reset(void)
{
	slm_at_host_uninit();
	slm_power_off_modem();
	LOG_PANIC();
	sys_reboot(SYS_REBOOT_COLD);
}

SLM_AT_CMD_CUSTOM(xreset, "AT#XRESET", handle_at_reset);
static int handle_at_reset(enum at_parser_cmd_type cmd_type, struct at_parser *, uint32_t)
{
	if (cmd_type != AT_PARSER_CMD_TYPE_SET) {
		return -EINVAL;
	}

	final_call(slm_reset);
	return 0;
}

static void slm_modemreset(void)
{
	/* The modem must be put in minimal function mode before being shut down. */
	slm_power_off_modem();

	unsigned int step = 1;
	int ret;

	ret = nrf_modem_lib_shutdown();
	if (ret != 0) {
		goto out;
	}
	++step;

#if defined(CONFIG_SLM_FULL_FOTA)
	if (slm_modem_full_fota) {
		slm_finish_modem_full_fota();
	}
#endif

	ret = nrf_modem_lib_init();

	if (slm_fota_type & DFU_TARGET_IMAGE_TYPE_ANY_MODEM) {
		slm_fota_post_process();
	}

out:
	if (ret) {
		/* Error; print the step that failed and its error code. */
		rsp_send("\r\n#XMODEMRESET: %u,%d\r\n", step, ret);
	} else {
		rsp_send("\r\n#XMODEMRESET: 0\r\n");
	}
	rsp_send_ok();
}

SLM_AT_CMD_CUSTOM(xmodemreset, "AT#XMODEMRESET", handle_at_modemreset);
static int handle_at_modemreset(enum at_parser_cmd_type cmd_type, struct at_parser *, uint32_t)
{
	if (cmd_type != AT_PARSER_CMD_TYPE_SET) {
		return -EINVAL;
	}

	/* Return immediately to allow the custom command handling in libmodem to finish processing,
	 * before restarting libmodem.
	 */
	final_call(slm_modemreset);

	return -SILENT_AT_COMMAND_RET;
}

SLM_AT_CMD_CUSTOM(xuuid, "AT#XUUID", handle_at_uuid);
static int handle_at_uuid(enum at_parser_cmd_type cmd_type, struct at_parser *, uint32_t)
{
	int ret;

	if (cmd_type != AT_PARSER_CMD_TYPE_SET) {
		return -EINVAL;
	}

	struct nrf_device_uuid dev = {0};

	ret = modem_jwt_get_uuids(&dev, NULL);
	if (ret) {
		LOG_ERR("Get device UUID error: %d", ret);
	} else {
		rsp_send("\r\n#XUUID: %s\r\n", dev.str);
	}

	return ret;
}

SLM_AT_CMD_CUSTOM(xdatactrl, "AT#XDATACTRL", handle_at_datactrl);
static int handle_at_datactrl(enum at_parser_cmd_type cmd_type, struct at_parser *parser,
			      uint32_t)
{
	int ret = 0;
	uint16_t time_limit, time_limit_min;

	switch (cmd_type) {
	case AT_PARSER_CMD_TYPE_SET:
		ret = at_parser_num_get(parser, 1, &time_limit);
		if (ret) {
			return ret;
		}
		if (time_limit > 0 && verify_datamode_control(time_limit, NULL)) {
			slm_datamode_time_limit = time_limit;
		} else {
			return -EINVAL;
		}
		break;

	case AT_PARSER_CMD_TYPE_READ:
		(void)verify_datamode_control(slm_datamode_time_limit, &time_limit_min);
		rsp_send("\r\n#XDATACTRL: %d,%d\r\n", slm_datamode_time_limit, time_limit_min);
		break;

	case AT_PARSER_CMD_TYPE_TEST:
		rsp_send("\r\n#XDATACTRL=<time_limit>\r\n");
		break;

	default:
		break;
	}

	return ret;
}

SLM_AT_CMD_CUSTOM(xclac, "AT#XCLAC", handle_at_clac);
static int handle_at_clac(enum at_parser_cmd_type cmd_type, struct at_parser *, uint32_t)
{
	if (cmd_type != AT_PARSER_CMD_TYPE_SET) {
		return -EINVAL;
	}

	/* Use AT_CMD_CUSTOM listing for extracting SLM AT commands. */
	extern struct nrf_modem_at_cmd_custom _nrf_modem_at_cmd_custom_list_start[];
	extern struct nrf_modem_at_cmd_custom _nrf_modem_at_cmd_custom_list_end[];
	size_t cmd_custom_count = _nrf_modem_at_cmd_custom_list_end -
				  _nrf_modem_at_cmd_custom_list_start;
	size_t base_cmd_len[cmd_custom_count];

	memset(base_cmd_len, 0, cmd_custom_count * sizeof(size_t));
	rsp_send("\r\n");
	for (size_t i = 0; i < cmd_custom_count; i++) {
		/* SLM at commands start with AT#X. */
		if (strncasecmp(_nrf_modem_at_cmd_custom_list_start[i].cmd, "AT#X",
				strlen("AT#X"))) {
			continue;
		}
		/* List commands without operations and list each command only once. */
		base_cmd_len[i] = strcspn(_nrf_modem_at_cmd_custom_list_start[i].cmd, "?=");
		bool duplicate = false;

		for (size_t j = 0; j < i; j++) {
			/* Compare length and command as we have AT commands such as
			 * AT#XSEND/AT#XSENDTO, AT#XFTP="whatever"
			 * and AT#XNRFCLOUD[=?]/AT#XNRFCLOUDPOS.
			 */
			if ((base_cmd_len[i] == base_cmd_len[j]) &&
			    !strncasecmp(_nrf_modem_at_cmd_custom_list_start[i].cmd,
					 _nrf_modem_at_cmd_custom_list_start[j].cmd,
					 base_cmd_len[i])) {
				duplicate = true;
				break;
			}
		}

		if (!duplicate) {
			rsp_send("%.*s\r\n", base_cmd_len[i],
				 _nrf_modem_at_cmd_custom_list_start[i].cmd);
		}
	}

	return 0;
}

int slm_at_init(void)
{
	int err;

#if POWER_PIN_IS_ENABLED
	k_work_init_delayable(&sleep_control.work, go_sleep_wk);
#endif

	err = slm_at_tcp_proxy_init();
	if (err) {
		LOG_ERR("TCP Server could not be initialized: %d", err);
		return -EFAULT;
	}
	err = slm_at_udp_proxy_init();
	if (err) {
		LOG_ERR("UDP Server could not be initialized: %d", err);
		return -EFAULT;
	}
	err = slm_at_socket_init();
	if (err) {
		LOG_ERR("TCPIP could not be initialized: %d", err);
		return -EFAULT;
	}
	err = slm_at_icmp_init();
	if (err) {
		LOG_ERR("ICMP could not be initialized: %d", err);
		return -EFAULT;
	}
#if defined(CONFIG_SLM_SMS)
	err = slm_at_sms_init();
	if (err) {
		LOG_ERR("SMS could not be initialized: %d", err);
		return -EFAULT;
	}
#endif
	err = slm_at_fota_init();
	if (err) {
		LOG_ERR("FOTA could not be initialized: %d", err);
		return -EFAULT;
	}
#if defined(CONFIG_SLM_NRF_CLOUD)
	err = slm_at_nrfcloud_init();
	if (err) {
		/* Allow nRF Cloud initialization to fail as sometimes JWT is missing
		 * especially during development.
		 */
		LOG_ERR("nRF Cloud could not be initialized: %d", err);
		err = 0;
	}
#endif
#if defined(CONFIG_SLM_GNSS)
	err = slm_at_gnss_init();
	if (err) {
		LOG_ERR("GNSS could not be initialized: %d", err);
		return -EFAULT;
	}
#endif
#if defined(CONFIG_SLM_FTPC)
	err = slm_at_ftp_init();
	if (err) {
		LOG_ERR("FTP could not be initialized: %d", err);
		return -EFAULT;
	}
#endif
#if defined(CONFIG_SLM_MQTTC)
	err = slm_at_mqtt_init();
	if (err) {
		LOG_ERR("MQTT could not be initialized: %d", err);
		return -EFAULT;
	}
#endif
#if defined(CONFIG_SLM_HTTPC)
	err = slm_at_httpc_init();
	if (err) {
		LOG_ERR("HTTP could not be initialized: %d", err);
		return -EFAULT;
	}
#endif
#if defined(CONFIG_SLM_GPIO)
	err = slm_at_gpio_init();
	if (err) {
		LOG_ERR("GPIO could not be initialized: %d", err);
		return -EFAULT;
	}
#endif
#if defined(CONFIG_SLM_TWI)
	err = slm_at_twi_init();
	if (err) {
		LOG_ERR("TWI could not be initialized: %d", err);
		return -EFAULT;
	}
#endif
#if defined(CONFIG_SLM_CARRIER)
	err = slm_at_carrier_init();
	if (err) {
		LOG_ERR("LwM2M carrier could not be initialized: %d", err);
		return -EFAULT;
	}
#endif
#if defined(CONFIG_LWM2M_CARRIER_SETTINGS)
	err = slm_at_carrier_cfg_init();
	if (err) {
		LOG_ERR("LwM2M carrier could not be initialized: %d", err);
		return -EFAULT;
	}
#endif
#if defined(CONFIG_SLM_CMUX)
	slm_cmux_init();
#endif
#if defined(CONFIG_SLM_PPP)
	err = slm_ppp_init();
	if (err) {
		LOG_ERR("PPP initialization failed. (%d)", err);
		return err;
	}
#endif
	return err;
}

void slm_at_uninit(void)
{
	int err;

	err = slm_at_tcp_proxy_uninit();
	if (err) {
		LOG_WRN("TCP Server could not be uninitialized: %d", err);
	}
	err = slm_at_udp_proxy_uninit();
	if (err) {
		LOG_WRN("UDP Server could not be uninitialized: %d", err);
	}
	err = slm_at_socket_uninit();
	if (err) {
		LOG_WRN("TCPIP could not be uninitialized: %d", err);
	}
	err = slm_at_icmp_uninit();
	if (err) {
		LOG_WRN("ICMP could not be uninitialized: %d", err);
	}
#if defined(CONFIG_SLM_SMS)
	err = slm_at_sms_uninit();
	if (err) {
		LOG_WRN("SMS could not be uninitialized: %d", err);
	}
#endif
	err = slm_at_fota_uninit();
	if (err) {
		LOG_WRN("FOTA could not be uninitialized: %d", err);
	}
#if defined(CONFIG_SLM_NRF_CLOUD)
	err = slm_at_nrfcloud_uninit();
	if (err) {
		LOG_WRN("nRF Cloud could not be uninitialized: %d", err);
	}
#endif
#if defined(CONFIG_SLM_GNSS)
	err = slm_at_gnss_uninit();
	if (err) {
		LOG_WRN("GNSS could not be uninitialized: %d", err);
	}
#endif
#if defined(CONFIG_SLM_FTPC)
	err = slm_at_ftp_uninit();
	if (err) {
		LOG_WRN("FTP could not be uninitialized: %d", err);
	}
#endif
#if defined(CONFIG_SLM_MQTTC)
	err = slm_at_mqtt_uninit();
	if (err) {
		LOG_WRN("MQTT could not be uninitialized: %d", err);
	}
#endif
#if defined(CONFIG_SLM_HTTPC)
	err = slm_at_httpc_uninit();
	if (err) {
		LOG_WRN("HTTP could not be uninitialized: %d", err);
	}
#endif
#if defined(CONFIG_SLM_TWI)
	err = slm_at_twi_uninit();
	if (err) {
		LOG_ERR("TWI could not be uninit: %d", err);
	}
#endif
#if defined(CONFIG_SLM_GPIO)
	err = slm_at_gpio_uninit();
	if (err) {
		LOG_ERR("GPIO could not be uninit: %d", err);
	}
#endif
#if defined(CONFIG_SLM_CARRIER)
	err = slm_at_carrier_uninit();
	if (err) {
		LOG_ERR("LwM2M carrier could not be uninitialized: %d", err);
	}
#endif
}
```

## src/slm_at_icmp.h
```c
/*
 * Copyright (c) 2019 Nordic Semiconductor ASA
 *
 * SPDX-License-Identifier: LicenseRef-Nordic-5-Clause
 */

#ifndef SLM_AT_ICMP_
#define SLM_AT_ICMP_

/**@file slm_at_icmp.h
 *
 * @brief Vendor-specific AT command for ICMP service.
 * @{
 */

/**
 * @brief Initialize ICMP AT command parser.
 *
 * @retval 0 If the operation was successful.
 *           Otherwise, a (negative) error code is returned.
 */
int slm_at_icmp_init(void);

/**
 * @brief Uninitialize ICMP AT command parser.
 *
 * @retval 0 If the operation was successful.
 *           Otherwise, a (negative) error code is returned.
 */
int slm_at_icmp_uninit(void);
/** @} */

#endif /* SLM_AT_ICMP_ */
```
